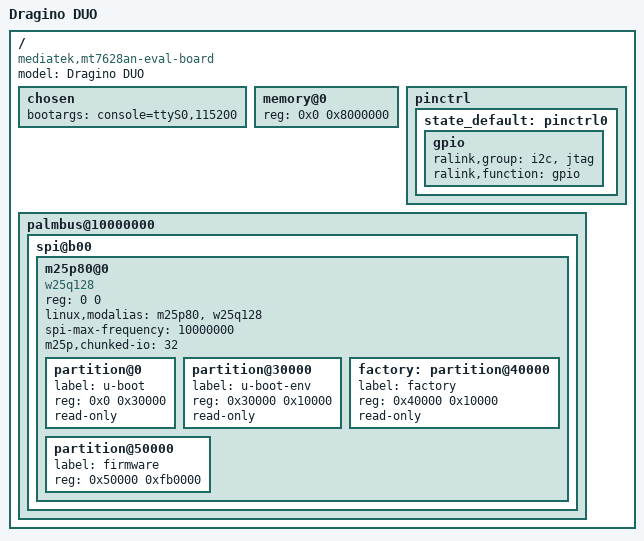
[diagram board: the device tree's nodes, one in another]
/dts-v1/;

/include/ "mt7628an.dtsi"

/ {
	compatible = "mediatek,mt7628an-eval-board", "mediatek,mt7628an-soc";
	model = "Dragino DUO";

	chosen {
		bootargs = "console=ttyS0,115200";
	};
	
	memory@0 {
		device_type = "memory";
		reg = <0x0 0x8000000>;
	};

	pinctrl {
		state_default: pinctrl0 {
			gpio {
				ralink,group = "i2c", "jtag";
				ralink,function = "gpio";
			};
		};
	};

	palmbus@10000000 {
		spi@b00 {
			status = "okay";

			m25p80@0 {
				#address-cells = <1>;
				#size-cells = <1>;
				compatible = "w25q128";
				reg = <0 0>;
				linux,modalias = "m25p80", "w25q128";
				spi-max-frequency = <10000000>;
				m25p,chunked-io = <32>;

				partition@0 {
					label = "u-boot";
					reg = <0x0 0x30000>;
					read-only;
				};

				partition@30000 {
					label = "u-boot-env";
					reg = <0x30000 0x10000>;
					read-only;
				};

				factory: partition@40000 {
					label = "factory";
					reg = <0x40000 0x10000>;
					read-only;
				};

				partition@50000 {
					label = "firmware";
					reg = <0x50000 0xfb0000>;
				};
			};
		};
	};
};
